AUTOSAR XML (schema 4-3-0)
package /App_PWM
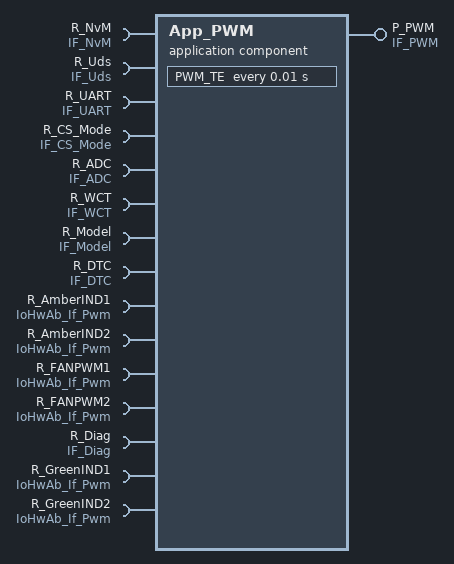
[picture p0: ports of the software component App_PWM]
  application sw component type App_PWM
    provide port P_PWM: nonqueued-sender-com-spec=PWM_STR, provided-interface=IF_PWM
    15 x require port:
      R_NvM: nonqueued-receiver-com-spec=NvM_STR, required-interface=IF_NvM
      R_Uds: nonqueued-receiver-com-spec=Uds_STR, required-interface=IF_Uds
      R_UART: nonqueued-receiver-com-spec=UART_STR, required-interface=IF_UART
      R_CS_Mode: required-com-specs=[ModeInit, NvMInit, ApplicationInit], required-interface=IF_CS_Mode
      R_ADC: nonqueued-receiver-com-spec=ADC_STR, required-interface=IF_ADC
      R_WCT: nonqueued-receiver-com-spec=WCT_STR, required-interface=IF_WCT
      R_Model: nonqueued-receiver-com-spec=Model_STR, required-interface=IF_Model
      R_DTC: nonqueued-receiver-com-spec=DTC_STR, required-interface=IF_DTC
      R_AmberIND1: required-com-specs=[SetDutyCycle, SetOutputToIdle], required-interface=IoHwAb_If_Pwm
      R_AmberIND2: required-com-specs=[SetOutputToIdle, SetDutyCycle], required-interface=IoHwAb_If_Pwm
      R_FANPWM1: required-com-specs=[SetDutyCycle, SetOutputToIdle], required-interface=IoHwAb_If_Pwm
      R_FANPWM2: required-com-specs=[SetOutputToIdle, SetDutyCycle], required-interface=IoHwAb_If_Pwm
      R_Diag: nonqueued-receiver-com-spec=Diag_STR, required-interface=IF_Diag
      R_GreenIND1: required-com-specs=[SetDutyCycle, SetOutputToIdle], required-interface=IoHwAb_If_Pwm
      R_GreenIND2: required-com-specs=[SetOutputToIdle, SetDutyCycle], required-interface=IoHwAb_If_Pwm
    behavior InternalBehavior: data-type-mapping=DataTypeMappingSet_WPC
      timing event TE_PWM_TE: start-on-event=PWM_TE, period=0.01
      runnable PWM_TE: symbol=PWM_TE_Runnable
        data-receive-point-by-arguments:
          8 x access, all with scope=COMMUNICATION-INTER-ECU:
            DRPBA_PWM_TE_R_ADC_ADC_u8_arr: accessed-variable=R_ADC.ADC_STR
            DRPBA_PWM_TE_R_Model_Structure: accessed-variable=R_Model.Model_STR
            DRPBA_PWM_TE_R_UART_Structure: accessed-variable=R_UART.UART_STR
            DRPBA_PWM_TE_R_Diag_Diag_STR: accessed-variable=R_Diag.Diag_STR
            DRPBA_PWM_TE_R_WCT_WCT_STR_ALL: accessed-variable=R_WCT.WCT_STR
            DRPBA_PWM_TE_R_DTC_DTC_STR: accessed-variable=R_DTC.DTC_STR
            DRPBA_PWM_TE_R_Uds_Uds_STR: accessed-variable=R_Uds.Uds_STR
            DRPBA_PWM_TE_R_NvM_NvM_STR: accessed-variable=R_NvM.NvM_STR
        data-send-points:
          access DSP_PWM_TE_P_PWM_u16_Arr64: accessed-variable=P_PWM.PWM_STR, scope=COMMUNICATION-INTER-ECU
        15 x sync call:
          SSCP_PWM_TE_R_CS_Mode_ApplicationInit: operation=R_CS_Mode.ApplicationInit
          SSCP_PWM_TE_R_CS_Mode_ModeInit: operation=R_CS_Mode.ModeInit
          SSCP_PWM_TE_R_CS_Mode_NvMInit: operation=R_CS_Mode.NvMInit
          SSCP_PWM_TE_R_FANPWM1_SetDutyCycle: operation=R_FANPWM1.SetDutyCycle
          SSCP_PWM_TE_R_FANPWM1_SetOutputToIdle: operation=R_FANPWM1.SetOutputToIdle
          SSCP_PWM_TE_R_FANPWM2_SetDutyCycle: operation=R_FANPWM2.SetDutyCycle
          SSCP_PWM_TE_R_FANPWM2_SetOutputToIdle: operation=R_FANPWM2.SetOutputToIdle
          SSCP_PWM_TE_R_AmberIND1_SetDutyCycle: operation=R_AmberIND1.SetDutyCycle
          SSCP_PWM_TE_R_AmberIND1_SetOutputToIdle: operation=R_AmberIND1.SetOutputToIdle
          SSCP_PWM_TE_R_AmberIND2_SetDutyCycle: operation=R_AmberIND2.SetDutyCycle
          SSCP_PWM_TE_R_AmberIND2_SetOutputToIdle: operation=R_AmberIND2.SetOutputToIdle
          SSCP_PWM_TE_R_GreenIND1_SetDutyCycle: operation=R_GreenIND1.SetDutyCycle
          SSCP_PWM_TE_R_GreenIND1_SetOutputToIdle: operation=R_GreenIND1.SetOutputToIdle
          SSCP_PWM_TE_R_GreenIND2_SetDutyCycle: operation=R_GreenIND2.SetDutyCycle
          SSCP_PWM_TE_R_GreenIND2_SetOutputToIdle: operation=R_GreenIND2.SetOutputToIdle
  sender receiver interface IF_PWM  # NFC SWC Output
    data PWM_STR: type=IDT_PWM_STR
